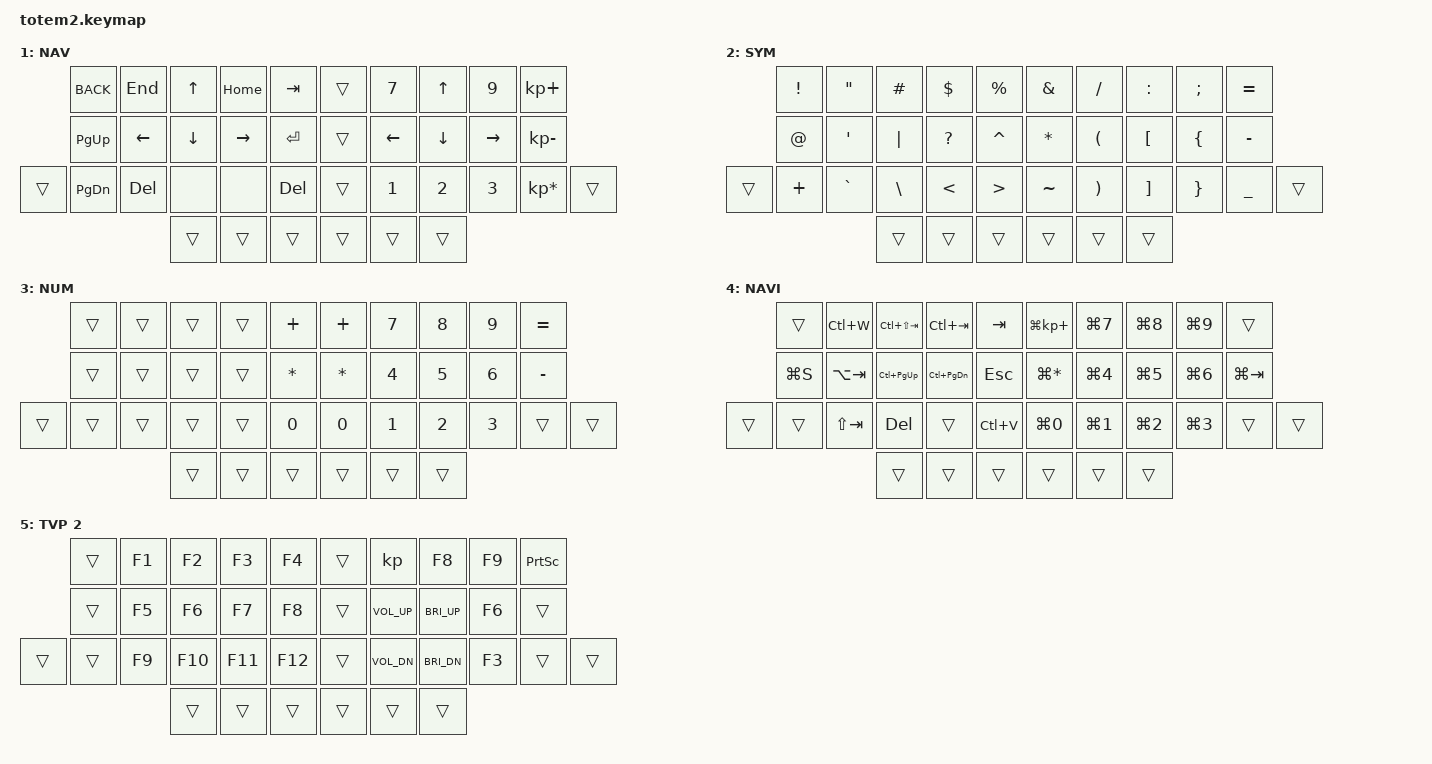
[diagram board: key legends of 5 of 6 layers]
//
//                                                        ▀▀▀▀▀     ▀▀▀▀▀          ▀▀█▀▀
//                                                        ▄▀▀▀▄  ▄  ▄▀▀▀▄  ▄  ▄▀▀▀▄  █  ▄▀▀▀▄
//                                                        █   █  █  █   █  █  █   █  █  █   █
//                                                         ▀▀▀   █   ▀▀▀   █   ▀▀▀   ▀   ▀▀▀
//                                                               █      ▄▄▄█▄▄▄    █   █  
//                                                               ▀      █  █  █     █▄█
//                                                             ▀▀▀▀▀    █  █  █      ▀
//                                                                      ▀  ▀  ▀
//
// ▄▄▄▄▄▄▄▄▄▄▄▄▄▄▄▄▄▄▄▄▄▄▄▄▄▄▄▄▄▄▄▄▄▄▄▄▄▄▄▄▄▄▄▄▄▄▄▄▄▄▄▄▄▄▄▄▄▄▄▄▄▄▄▄▄▄▄▄▄▄▄▄▄▄▄▄▄▄▄▄▄▄▄▄▄▄▄▄▄▄▄▄▄▄▄▄▄▄▄▄▄▄▄▄▄▄▄▄▄▄▄▄▄▄▄▄▄▄▄▄▄▄▄▄▄▄▄▄▄▄▄▄▄▄▄▄▄▄▄▄▄▄▄▄▄▄▄▄▄
       

#include <behaviors.dtsi>
#include <dt-bindings/zmk/keys.h>
#include <dt-bindings/zmk/bt.h>
#include <dt-bindings/zmk/outputs.h>

#define BASE 0
#define NAV  1
#define SYM  2
#define NUM  3
#define TVP1 4
#define TVP2 5

&mt {
  quick-tap-ms = <100>;
  global-quick-tap;
  flavor = "tap-preferred";
  tapping-term-ms = <170>;
};

/ {
     combos {
            compatible = "zmk,combos";
            combo_esc {
                timeout-ms = <50>;
                key-positions = <0 1>;
                bindings = <&kp ESC>;
            };
            combo_tvp {
                timeout-ms = <100>;
                key-positions = <11 12 13>;
                bindings = <&tog TVP1>;
            };
    };

    macros {
        gif: gif {
            label = "giphy";
            compatible = "zmk,behavior-macro";
            #binding-cells = <0>;
            bindings
                = <&macro_press &kp LSHFT>
                , <&macro_tap &kp N2>
                , <&macro_release &kp LSHFT>
                , <&macro_tap &kp G &kp I &kp F>
                ;
        };
    };

        keymap {
                compatible = "zmk,keymap";
// ▄▄▄▄▄▄▄▄▄▄▄▄▄▄▄▄▄▄▄▄▄▄▄▄▄▄▄▄▄▄▄▄▄▄▄▄▄▄▄▄▄▄▄▄▄▄▄▄▄▄▄▄▄▄▄▄▄▄▄▄▄▄▄▄▄▄▄▄▄▄▄▄▄▄▄▄▄▄▄▄▄▄▄▄▄▄▄▄▄▄▄▄▄▄▄▄▄▄▄▄▄▄▄▄▄▄▄▄▄▄▄▄▄▄▄▄▄▄▄▄▄▄▄▄▄▄▄▄▄▄▄▄▄▄▄▄▄▄▄▄▄▄▄▄▄▄▄▄▄

                base_layer {
// ┏━━━━━━━━━━━━━━━━━━━━━━━━━━━━━━━━━━━━━━━┓0
label= "BASE"                              ;
// ┗━━━━━━━━━━━━━━━━━━━━━━━━━━━━━━━━━━━━━━━┛
//             ┏━━━━━━━━━━━┳━━━━━━━━━━━┳━━━━━━━━━━━┳━━━━━━━━━━━┳━━━━━━━━━━━┓   ┏━━━━━━━━━━━┳━━━━━━━━━━━┳━━━━━━━━━━━┳━━━━━━━━━━━┳━━━━━━━━━━━┓
//             ┃     Q     ┃     W     ┃     F     ┃     P     ┃     B     ┃   ┃     J     ┃     L     ┃     U     ┃     Y     ┃     ;     ┃
//             ┣━━━━━━━━━━━╋━━━━━━━━━━━╋━━━━━━━━━━━╋━━━━━━━━━━━╋━━━━━━━━━━━┫   ┣━━━━━━━━━━━╋━━━━━━━━━━━╋━━━━━━━━━━━╋━━━━━━━━━━━╋━━━━━━━━━━━┫
//             ┃     A     ┃     R     ┃     S     ┃     T     ┃     G     ┃   ┃     M     ┃     N     ┃     E     ┃     I     ┃     O     ┃
// ┏━━━━━━━━━━━╋━━━━━━━━━━━╋━━━━━━━━━━━╋━━━━━━━━━━━╋━━━━━━━━━━━╋━━━━━━━━━━━┫   ┣━━━━━━━━━━━╋━━━━━━━━━━━╋━━━━━━━━━━━╋━━━━━━━━━━━╋━━━━━━━━━━━╋━━━━━━━━━━━┓
// ┃    MO(3)  ┃     Z     ┃     X     ┃     C     ┃     D     ┃     V     ┃   ┃     K     ┃     H     ┃     ,     ┃     .     ┃     /     ┃  RETURN   ┃
// ┗━━━━━━━━━━━┻━━━━━━━━━━━┻━━━━━━━━━━━╋━━━━━━━━━━━╋━━━━━━━━━━━╋━━━━━━━━━━━┫   ┣━━━━━━━━━━━╋━━━━━━━━━━━╋━━━━━━━━━━━╋━━━━━━━━━━━┻━━━━━━━━━━━┻━━━━━━━━━━━┛
//                                     ┃   MO(4)   ┃   SPACE   ┃   LT(1)   ┃   ┃  LSHIFT   ┃   LT(1)   ┃    MO(2)  ┃
//                                     ┗━━━━━━━━━━━┻━━━━━━━━━━━┻━━━━━━━━━━━┛   ┗━━━━━━━━━━━┻━━━━━━━━━━━┻━━━━━━━━━━━┛
 bindings = <
// ╷           ╷           ╷           ╷           ╷           ╷           ╷   ╷           ╷           ╷           ╷           ╷           ╷           ╷

                &kp Q       &kp W       &kp F       &kp P       &kp B           &kp J       &kp L       &kp U       &kp Y       &kp SEMI
                &kp A       &mt LGUI R  &mt LSHFT S &mt LCTRL T &mt LALT G      &mt LALT M  &mt LCTRL N &mt LSHFT E &mt LGUI I  &kp O
    &mo 3       &kp Z       &kp X       &kp C       &kp D       &kp V           &kp K       &kp H       &kp COMMA   &kp DOT     &kp 5 RET    &lt 5 RET
                                        &mo 4       &kp SPACE   &lt 1 ESC       &sk LSHFT   &lt 1 BSPC  &mo 2
                        >;
                };

// ▄▄▄▄▄▄▄▄▄▄▄▄▄▄▄▄▄▄▄▄▄▄▄▄▄▄▄▄▄▄▄▄▄▄▄▄▄▄▄▄▄▄▄▄▄▄▄▄▄▄▄▄▄▄▄▄▄▄▄▄▄▄▄▄▄▄▄▄▄▄▄▄▄▄▄▄▄▄▄▄▄▄▄▄▄▄▄▄▄▄▄▄▄▄▄▄▄▄▄▄▄▄▄▄▄▄▄▄▄▄▄▄▄▄▄▄▄▄▄▄▄▄▄▄▄▄▄▄▄▄▄▄▄▄▄▄▄▄▄▄▄▄▄▄▄▄▄▄▄


                nav_layer {
// ┏━━━━━━━━━━━━━━━━━━━━━━━━━━━━━━━━━━━━━━━┓1
label= "NAV"                               ;
 bindings = <
// ╷           ╷           ╷           ╷           ╷           ╷           ╷   ╷           ╷           ╷           ╷           ╷           ╷           ╷

                &kp K_BACK  &kp END     &kp UP      &kp HOME   &kp TAB          &trans     &kp N7     &kp UP      &kp N9      &kp KP_PLUS
                &kp PG_UP   &kp LEFT    &kp DOWN    &kp RIGHT  &kp RET          &trans     &kp LEFT   &kp DOWN    &kp RIGHT   &kp KP_MINUS
    &trans      &kp PG_DN   &kp DEL     &none       &none      &kp DEL          &trans     &kp N1     &kp N2      &kp N3      &kp KP_MULTIPLY &trans
                                        &trans      &trans     &trans           &trans     &trans     &trans
                        >;
                };

// ▄▄▄▄▄▄▄▄▄▄▄▄▄▄▄▄▄▄▄▄▄▄▄▄▄▄▄▄▄▄▄▄▄▄▄▄▄▄▄▄▄▄▄▄▄▄▄▄▄▄▄▄▄▄▄▄▄▄▄▄▄▄▄▄▄▄▄▄▄▄▄▄▄▄▄▄▄▄▄▄▄▄▄▄▄▄▄▄▄▄▄▄▄▄▄▄▄▄▄▄▄▄▄▄▄▄▄▄▄▄▄▄▄▄▄▄▄▄▄▄▄▄▄▄▄▄▄▄▄▄▄▄▄▄▄▄▄▄▄▄▄▄▄▄▄▄▄▄▄

                sim_layer {
// ┏━━━━━━━━━━━━━━━━━━━━━━━━━━━━━━━━━━━━━━━┓2
label= "SYM"                               ;
// ┗━━━━━━━━━━━━━━━━━━━━━━━━━━━━━━━━━━━━━━━┛
//             ┏━━━━━━━━━━━┳━━━━━━━━━━━┳━━━━━━━━━━━┳━━━━━━━━━━━┳━━━━━━━━━━━┓   ┏━━━━━━━━━━━┳━━━━━━━━━━━┳━━━━━━━━━━━┳━━━━━━━━━━━┳━━━━━━━━━━━┓
//             ┃     !     ┃     "     ┃     #     ┃     $     ┃     %     ┃   ┃     &     ┃     /     ┃     :     ┃     ;     ┃     =     ┃
//             ┣━━━━━━━━━━━╋━━━━━━━━━━━╋━━━━━━━━━━━╋━━━━━━━━━━━╋━━━━━━━━━━━┫   ┣━━━━━━━━━━━╋━━━━━━━━━━━╋━━━━━━━━━━━╋━━━━━━━━━━━╋━━━━━━━━━━━┫
//             ┃     @     ┃     '     ┃     |     ┃     ?     ┃     ^     ┃   ┃     *     ┃     (     ┃     [     ┃     {     ┃     -     ┃
// ┏━━━━━━━━━━━╋━━━━━━━━━━━╋━━━━━━━━━━━╋━━━━━━━━━━━╋━━━━━━━━━━━╋━━━━━━━━━━━┫   ┣━━━━━━━━━━━╋━━━━━━━━━━━╋━━━━━━━━━━━╋━━━━━━━━━━━╋━━━━━━━━━━━╋━━━━━━━━━━━┓
// ┃           ┃     +     ┃     `     ┃     \     ┃     <     ┃     >     ┃   ┃     ~     ┃     )     ┃     ]     ┃     }     ┃     _     ┃           ┃
// ┗━━━━━━━━━━━┻━━━━━━━━━━━┻━━━━━━━━━━━╋━━━━━━━━━━━╋━━━━━━━━━━━╋━━━━━━━━━━━┫   ┣━━━━━━━━━━━╋━━━━━━━━━━━╋━━━━━━━━━━━╋━━━━━━━━━━━┻━━━━━━━━━━━┻━━━━━━━━━━━┛
//                                     ┃           ┃           ┃           ┃   ┃           ┃           ┃           ┃
//                                     ┗━━━━━━━━━━━┻━━━━━━━━━━━┻━━━━━━━━━━━┛   ┗━━━━━━━━━━━┻━━━━━━━━━━━┻━━━━━━━━━━━┛
 bindings = <
// ╷           ╷           ╷           ╷           ╷           ╷           ╷   ╷           ╷           ╷           ╷           ╷           ╷           ╷

                &kp EXCL    &kp DQT     &kp HASH    &kp DLLR    &kp PRCNT       &kp AMPS    &kp FSLH    &kp COLON  &kp SEMI    &kp EQUAL
                &kp AT      &kp SQT     &kp PIPE    &kp QMARK   &kp CARET       &kp ASTRK   &kp LPAR    &kp LBKT   &kp LBRC    &kp MINUS
    &trans      &kp PLUS    &kp GRAVE   &kp BSLH    &kp LT      &kp GT          &kp TILDE   &kp RPAR    &kp RBKT   &kp RBRC    &kp UNDER   &trans
                                        &trans      &trans      &trans          &trans      &trans      &trans      
                        >;
                };


// ▄▄▄▄▄▄▄▄▄▄▄▄▄▄▄▄▄▄▄▄▄▄▄▄▄▄▄▄▄▄▄▄▄▄▄▄▄▄▄▄▄▄▄▄▄▄▄▄▄▄▄▄▄▄▄▄▄▄▄▄▄▄▄▄▄▄▄▄▄▄▄▄▄▄▄▄▄▄▄▄▄▄▄▄▄▄▄▄▄▄▄▄▄▄▄▄▄▄▄▄▄▄▄▄▄▄▄▄▄▄▄▄▄▄▄▄▄▄▄▄▄▄▄▄▄▄▄▄▄▄▄▄▄▄▄▄▄▄▄▄▄▄▄▄▄▄▄▄▄

                adjust_layer {
// ┏━━━━━━━━━━━━━━━━━━━━━━━━━━━━━━━━━━━━━━━┓3
label= "NUM"                               ;
// ┗━━━━━━━━━━━━━━━━━━━━━━━━━━━━━━━━━━━━━━━┛
 bindings = <
// ╷           ╷           ╷           ╷           ╷           ╷           ╷   ╷           ╷           ╷           ╷           ╷           ╷           ╷

                &trans     &trans      &trans      &trans      &kp PLUS          &kp PLUS    &kp N7      &kp N8     &kp N9       &kp EQUAL
                &trans     &trans      &trans      &trans      &kp ASTRK         &kp ASTRK   &kp N4      &kp N5     &kp N6       &kp MINUS  
    &trans      &trans     &trans      &trans      &trans      &kp N0            &kp N0      &kp N1      &kp N2     &kp N3       &trans          &trans
                                       &trans      &trans      &trans            &trans      &trans      &trans      
                        >;
                };

// ▄▄▄▄▄▄▄▄▄▄▄▄▄▄▄▄▄▄▄▄▄▄▄▄▄▄▄▄▄▄▄▄▄▄▄▄▄▄▄▄▄▄▄▄▄▄▄▄▄▄▄▄▄▄▄▄▄▄▄▄▄▄▄▄▄▄▄▄▄▄▄▄▄▄▄▄▄▄▄▄▄▄▄▄▄▄▄▄▄▄▄▄▄▄▄▄▄▄▄▄▄▄▄▄▄▄▄▄▄▄▄▄▄▄▄▄▄▄▄▄▄▄▄▄▄▄▄▄▄▄▄▄▄▄▄▄▄▄▄▄▄▄▄▄▄▄▄▄▄


                tvp1_layer {
label= "NAVI"                               ;
 bindings = <
// ╷           ╷           ╷           ╷           ╷           ╷           ╷   ╷           ╷           ╷           ╷           ╷           ╷           ╷

               &trans      &kp LC(W)   &kp LC(LS(TAB)) &kp LC(TAB) &kp TAB      &kp LG(KP_PLUS) &kp LG(N7) &kp LG(N8) &kp LG(N9) &trans
               &kp LG(S)   &kp LA(TAB) &kp LC(PG_UP) &kp LC(PG_DN) &kp ESC      &kp LG(ASTRK)   &kp LG(N4) &kp LG(N5) &kp LG(N6) &kp LG(TAB)
    &trans     &trans      &kp LS(TAB) &kp DEL       &trans        &kp LC(V)    &kp LG(N0)      &kp LG(N1) &kp LG(N2) &kp LG(N3) &trans      &trans
                                       &trans        &trans        &trans       &trans          &trans     &trans    
                        >;
                };

// ▄▄▄▄▄▄▄▄▄▄▄▄▄▄▄▄▄▄▄▄▄▄▄▄▄▄▄▄▄▄▄▄▄▄▄▄▄▄▄▄▄▄▄▄▄▄▄▄▄▄▄▄▄▄▄▄▄▄▄▄▄▄▄▄▄▄▄▄▄▄▄▄▄▄▄▄▄▄▄▄▄▄▄▄▄▄▄▄▄▄▄▄▄▄▄▄▄▄▄▄▄▄▄▄▄▄▄▄▄▄▄▄▄▄▄▄▄▄▄▄▄▄▄▄▄▄▄▄▄▄▄▄▄▄▄▄▄▄▄▄▄▄▄▄▄▄▄▄▄


                tvp2_layer {
// ┏━━━━━━━━━━━━━━━━━━━━━━━━━━━━━━━━━━━━━━━┓5
label= "TVP 2"                             ;
 bindings = <
// ╷           ╷           ╷           ╷           ╷           ╷           ╷   ╷           ╷           ╷           ╷           ╷           ╷           ╷

                &trans     &kp F1     &kp F2      &kp F3        &kp F4          &trans       &kp          &kp F8       &kp F9   &kp PSCRN
                &trans     &kp F5     &kp F6      &kp F7        &kp F8          &trans       &kp C_VOL_UP &kp C_BRI_UP &kp F6   &trans  
    &trans      &trans     &kp F9     &kp F10     &kp F11       &kp F12         &trans       &kp C_VOL_DN &kp C_BRI_DN &kp F3   &trans     &trans         
                                      &trans      &trans        &trans          &trans       &trans       &trans
                        >;
                };

// ▄▄▄▄▄▄▄▄▄▄▄▄▄▄▄▄▄▄▄▄▄▄▄▄▄▄▄▄▄▄▄▄▄▄▄▄▄▄▄▄▄▄▄▄▄▄▄▄▄▄▄▄▄▄▄▄▄▄▄▄▄▄▄▄▄▄▄▄▄▄▄▄▄▄▄▄▄▄▄▄▄▄▄▄▄▄▄▄▄▄▄▄▄▄▄▄▄▄▄▄▄▄▄▄▄▄▄▄▄▄▄▄▄▄▄▄▄▄▄▄▄▄▄▄▄▄▄▄▄▄▄▄▄▄▄▄▄▄▄▄▄▄▄▄▄▄▄▄▄

        };
}
